# M2354 register map
File version: 1.0
Registers are 32-bit, read-write, reset 0x0 unless marked. A register's access mark holds for its fields unless they carry their own. Offsets are from the block's base; [hi:lo] are bit positions; {n}, {i} and the like mark numbered series; 'fields as' and 'values as' point back to an identical list.

## TAMPER — Tamper Register Map
Base 0x400BD000
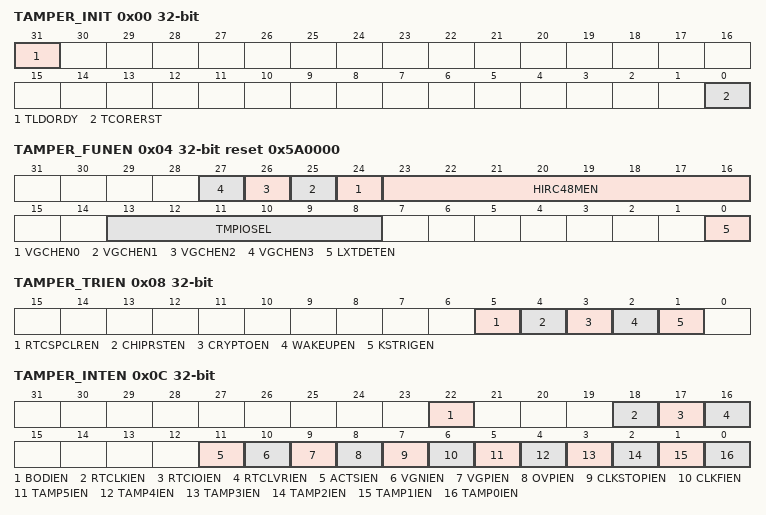
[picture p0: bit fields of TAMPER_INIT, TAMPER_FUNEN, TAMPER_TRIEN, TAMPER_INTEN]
0x00 TAMPER_INIT — Tamper Function Initiation Register
  [31] TLDORDY ro — Voltage Regulator Power Ready (Read Only)
    0=The power status of voltage regulator is not ready; 1=The power status of voltage regulator is ready
  [0] TCORERST — Tamper Core Reset
    0=Write 0x5500; the Tamper core block reset will be released; 1=Write 0x55AA; the Tamper core block will be reset
0x04 TAMPER_FUNEN reset 0x5A0000 — Tamper Block Function Enable Register
  [n+24] VGCHEN{n} (n=0..3) — Voltage Glitch Channel {n} Enable Bit. Note: To avoid the voltage glitch when the voltage channel is enabled, it is better to detect the voltage glitch about 150us after the channel is enabled.
    0=Voltage glitch channel {n} Disabled; 1=Voltage glitch channel {n} Enabled
  [23:16] HIRC48MEN — HIRC48M Enable Bit. The HIRC48M is disabled when these bits equal 0x5A, otherwise it will be enabled with any other values.
  [13:8] TMPIOSEL — Tamper I/O Detection Selection Bit
    0=Write 0x90/0xA0/0xB0/0xC0/0xD0/0xE0 for tamper I/O 0~5; the I/O tamper function is detected through RTC block; 1=Write 0x94/0xA4/0xB4/0xC4/0xD4/0xE4 for tamper I/O 0~5; the I/O tamper function is detected through Tamper block
  [0] LXTDETEN — LXT Clock Detection Enable Bit
    0=Write 0x40; the LXT clock detection Disabled; 1=Write 0x44; the LXT clock detection Enabled
0x08 TAMPER_TRIEN — Tamper Trigger Enable Register
  [5] RTCSPCLREN — RTC Spare Register Clear Enable Bit
    0=Tamper event trigger RTC spare register reset Disabled; 1=Tamper event trigger RTC spare register reset Enabled
  [4] CHIPRSTEN — Chip Reset Enable Bit
    0=Tamper event trigger chip reset Disabled; 1=Tamper event trigger chip reset Enabled
  [3] CRYPTOEN — Crypto Enable Bit
    0=Tamper event clear Crypto Disabled; 1=Tamper event clear Crypto Enabled
  [2] WAKEUPEN — Wakeup Enable Bit
    0=Tamper wakeup event Disabled; 1=Tamper wakeup event Enabled
  [1] KSTRIGEN — Key Store Trigger Enable Bit
    0=Tamper event is detected and to trigger Key Store Disabled; 1=Tamper event is detected and to trigger Key Store Enabled
0x0C TAMPER_INTEN — Tamper Event Interrupt Enable Register
  [22] BODIEN — BOD Event Interrupt Enable Bit
    0=Brown-out event interrupt Disabled; 1=Brown-out event interrupt Enabled
  [18] RTCLKIEN — RTC Clock Monitor Detection Event Interrupt Enable Bit
    0=RTC clock monitor event interrupt Disabled; 1=RTC clock monitor event interrupt Enabled
  [17] RTCIOIEN — RTC Tamper I/O Event Interrupt Enable Bit
    0=RTC tamper I/O detection event interrupt Disabled; 1=RTC tamper I/O detection event interrupt Enabled
  [16] RTCLVRIEN — RTC Low Voltage Detection Event Interrupt Enable Bit
    0=VBAT low voltage detection event interrupt Disabled; 1=VBAT low voltage detection event interrupt Enabled
  [11] ACTSIEN — Active Shield Event Interrupt Enable Bit
    0=Active shield event interrupt Disabled; 1=Active shield event interrupt Enabled
  [10] VGNIEN — Voltage Glitch Negative Detection Event Interrupt Enable Bit
    0=LDO_CAP negative glitch event interrupt Disabled; 1=LDO_CAP negative glitch event interrupt Enabled
  [9] VGPIEN — Voltage Glitch Positive Detection Event Interrupt Enable Bit
    0=LDO_CAP positive glitch event interrupt Disabled; 1=LDO_CAP positive glitch event interrupt Enabled
  [8] OVPIEN — VDD Over Voltage Protect Detection Interrupt Enable Bit. Note: The function enable of the over voltage detection is defined in system manager.
    0=Detect VDD over voltage protect detection interrupt Disabled; 1=Detect VDD over voltage protect detection interrupt Enabled
  [7] CLKSTOPIEN — LXT Clock Frequency Monitor Stop Event Interrupt Enable Bit
    0=LXT frequency stop event interrupt Disabled; 1=LXT frequency stop event interrupt Enabled
  [6] CLKFIEN — LXT Clock Frequency Monitor Fail Event Interrupt Enable Bit
    0=LXT frequency fail event interrupt Disabled; 1=LXT frequency fail event interrupt Enabled
  [5] TAMP5IEN — Tamper 5 or Pair 2 Event Interrupt Enable Bit
    0=Tamper 5 or Pair 2 event interrupt Disabled; 1=Tamper 5 or Pair 2 event interrupt Enabled
  [4] TAMP4IEN — Tamper 4 Event Interrupt Enable Bit
    0=Tamper 4 event interrupt Disabled; 1=Tamper 4 event interrupt Enabled
  [3] TAMP3IEN — Tamper 3 or Pair 1 Event Interrupt Enable Bit
    0=Tamper 3 or Pair 1 event interrupt Disabled; 1=Tamper 3 or Pair 1 event interrupt Enabled
  [2] TAMP2IEN — Tamper 2 Event Interrupt Enable Bit
    0=Tamper 2 event interrupt Disabled; 1=Tamper 2 event interrupt Enabled
  [1] TAMP1IEN — Tamper 1 or Pair 0 Event Interrupt Enable Bit
    0=Tamper 1 or Pair 0 event interrupt Disabled; 1=Tamper 1 or Pair 0 event interrupt Enabled
  [0] TAMP0IEN — Tamper 0 Event Interrupt Enable Bit
    0=Tamper 0 event interrupt Disabled; 1=Tamper 0 event interrupt Enabled
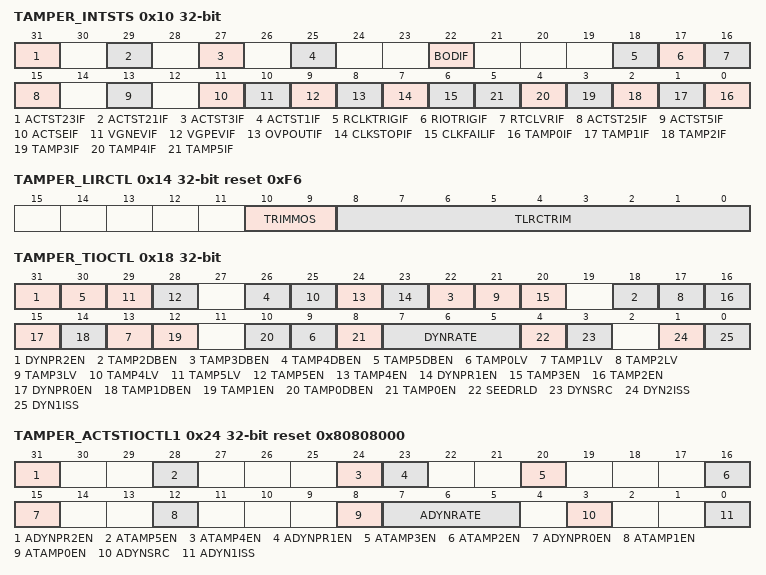
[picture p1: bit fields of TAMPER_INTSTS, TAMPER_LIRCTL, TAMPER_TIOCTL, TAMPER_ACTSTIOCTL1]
0x10 TAMPER_INTSTS — Tamper Interrupt Status Register
  [31] ACTST23IF — 2th Active Shield Tamper 3 Event Interrupt Flag. Note: Write 1 to clear this bit.
    0=No Active shield Tamper 3 event interrupt flag is generated; 1=2th Active shield Tamper 3 event interrupt flag is generated
  [29] ACTST21IF — 2th Active Shield Tamper 1 Event Interrupt Flag. Note: Write 1 to clear this bit.
    0=No Active shield Tamper 1 event interrupt flag is generated; 1=2th Active shield Tamper 1 event interrupt flag is generated
  [27] ACTST3IF — Active Shield Tamper 3 Event Interrupt Flag. Note: Write 1 to clear this bit.
    0=No Active shield Tamper 3 event interrupt flag is generated; 1=Active shield Tamper 3 event interrupt flag is generated
  [25] ACTST1IF — Active Shield Tamper 1 Event Interrupt Flag. Note: Write 1 to clear this bit.
    0=No Active shield Tamper 1 event interrupt flag is generated; 1=Active shield Tamper 1 event interrupt flag is generated
  [22] BODIF — BOD Event Interrupt Flag. Note: It is used to detect the LDO_CAP. Write 1 to clear this bit.
    0=Brown-out event interrupt flag is no detected; 1=Brown-out interrupt flag is detected
  [18] RCLKTRIGIF — RTC Clock Monitor Detection Event Interrupt Flag
    0=There is no RTC clock monitor detection event interrupt flag; 1=There is RTC clock monitor detection event interrupt flag
  [17] RIOTRIGIF — RTC Tamper I/O Event Interrupt Flag
    0=There is no RTC tamper I/O detection event interrupt flag; 1=There is RTC tamper I/O detection event interrupt flag
  [16] RTCLVRIF — RTC Low Voltage Detection Event Interrupt Flag
    0=VBAT low voltage detection event interrupt flag is not detected; 1=VBAT low voltage detection event interrupt flag is detected
  [15] ACTST25IF — Active Shield Tamper 5 Event Interrupt Flag. Note: Write 1 to clear this bit.
    0=No Active shield Tamper 5 event interrupt flag is generated; 1=2th Active shield Tamper 5 event interrupt flag is generated
  [13] ACTST5IF — Active Shield Tamper 5 Event Interrupt Flag. Note: Write 1 to clear this bit.
    0=No Active shield Tamper 5 event interrupt flag is generated; 1=Active shield Tamper 5 event interrupt flag is generated
  [11] ACTSEIF — Active Shield Event Detection Interrupt Flag. Note: Write 1 to clear this bit after all of ACTSTxIF bits have been cleaned.
    0=Active shield event interrupt flag is not detected; 1=Active shield event interrupt flag is detected including the voltage of voltage regulator and GND attack
  [10] VGNEVIF — Voltage Glitch Negative Detection Interrupt Flag. Note: It can be written 1 to clear only (No clear by TCORERST)
    0=LDO_CAP negative glitch is not detected; 1=LDO_CAP negative glitch is detected
  [9] VGPEVIF — Voltage Glitch Positive Detection Interrupt Flag. Note: It can be written 1 to clear only (No clear by TCORERST)
    0=LDO_CAP positive glitch is not detected; 1=LDO_CAP positive glitch is detected
  [8] OVPOUTIF — VDD Over Voltage Event Interrupt Flag. Note: Write 1 to clear this bit.
    0=VDD no over voltage is detected; 1=VDD over voltage is detected
  [7] CLKSTOPIF — LXT Clock Frequency Monitor Stop Event Interrupt Flag. Note 1: Write 1 to clear this bit to 0. Note 2: LXT detector will be automatically disabled when Fail/Stop flag rises, and resumes after Fail/Stop flag is cleared.
    0=LXT frequency is normal; 1=LXT frequency is almost stopped
  [6] CLKFAILIF — LXT Clock Frequency Monitor Fail Event Interrupt Flag. Note 1: Write 1 to clear this bit to 0. Note 2: LXT detector will be automatically disabled when Fail/Stop flag rises, and resumes after Fail/Stop flag is cleared.
    0=LXT frequency is normal; 1=LXT frequency is abnormal
  [n] TAMP{n}IF (n=0..5) — Tamper {n} Event Interrupt Flag. Note: Write 1 to clear this bit.
    0=No Tamper {n} event interrupt flag is generated; 1=Tamper {n} event interrupt flag is generated
0x14 TAMPER_LIRCTL reset 0xF6 — Tamper LIRC Control Register
  [10:9] TRIMMOS — Tamper TLIRC32K Trim MOS Value. TLIRC32K trim MOS value setting
  [8:0] TLRCTRIM — Tamper TLIRC32K Trim Value. TLIRC32K trim value setting
0x18 TAMPER_TIOCTL — Tamper I/O Function Control Register
  [31] DYNPR2EN — Dynamic Pair 2 Enable Bit
    0=Static detect; 1=Dynamic detect
  [4n+10] TAMP{n}DBEN (n=2..5) — Tamper {n} De-bounce Enable Bit
    0=Tamper {n} de-bounce Disabled; 1=Tamper {n} de-bounce Enabled. Tamper detection pin will sync 1 RTC clock
  [4n+9] TAMP{n}LV (n=0..5) — Tamper {n} Level. This bit depends on level attribute of tamper pin for static tamper detection.
    0=Detect voltage level is low; 1=Detect voltage level is high
  [28] TAMP5EN — Tamper 5 Detect Enable Bit. Note: The reference is RTC-clock. Tamper detector needs sync 2 ~ 3 RTC-clock.
    0=Tamper 5 detect Disabled; 1=Tamper 5 detect Enabled
  [24] TAMP4EN — Tamper4 Detect Enable Bit. Note: The reference is RTC-clock. Tamper detector needs sync 2 ~ 3 RTC-clock.
    0=Tamper 4 detect Disabled; 1=Tamper 4 detect Enabled
  [23] DYNPR1EN — Dynamic Pair 1 Enable Bit
    0=Static detect; 1=Dynamic detect
  [20] TAMP3EN — Tamper 3 Detect Enable Bit. Note: The reference is RTC-clock. Tamper detector needs sync 2 ~ 3 RTC-clock.
    0=Tamper 3 detect Disabled; 1=Tamper 3 detect Enabled
  [16] TAMP2EN — Tamper 2 Detect Enable Bit. Note: The reference is RTC-clock. Tamper detector need sync 2 ~ 3 RTC-clock.
    0=Tamper 2 detect Disabled; 1=Tamper 2 detect Enabled
  [15] DYNPR0EN — Dynamic Pair 0 Enable Bit
    0=Static detect; 1=Dynamic detect
  [14] TAMP1DBEN — Tamper 1 De-bounce Enable Bit
    0=Tamper 1 de-bounce Disabled; 1=Tamper 1 de-bounce Enabled, tamper detection pin will sync 1 RTC clock
  [12] TAMP1EN — Tamper 1 Detect Enable Bit. Note: The reference is RTC-clock. Tamper detector needs sync 2 ~ 3 RTC-clock.
    0=Tamper 1 detect Disabled; 1=Tamper 1 detect Enabled
  [10] TAMP0DBEN — Tamper 0 De-bounce Enable Bit
    0=Tamper 0 de-bounce Disabled; 1=Tamper 0 de-bounce Enabled. Tamper detection pin will sync 1 RTC clock
  [8] TAMP0EN — Tamper0 Detect Enable Bit. Note: The reference is RTC-clock. Tamper detector needs sync 2 ~ 3 RTC-clock.
    0=Tamper 0 detect Disabled; 1=Tamper 0 detect Enabled
  [7:5] DYNRATE — Dynamic Change Rate. This item is choice the dynamic tamper output change rate. Note: After revising this field, setting SEEDRLD (TAMPER_TIOCTL[4]) can reload change rate immediately.
    {v}={v+26} * RTC_CLK (v=0..3); {v}={v+206} * RTC_CLK (v=4..7)
  [4] SEEDRLD — Reload New Seed for PRNG Engine. Setting this bit, the tamper configuration will be reloaded. Note 1: Before this bit is set, the tamper configuration should be set to complete and this bit will be auto clear to 0 after reload new seed completed. Note 2: The reference is RTC-clock. Tamper detector needs sync 2 ~ 3 RTC-clock.
    0=Generating key based on the current seed; 1=Reload new seed
  [3] DYNSRC — Dynamic Reference Pattern. This field determines the new reference pattern when current pattern run out in dynamic pair mode. Note: After this bit is modified, the SEEDRLD (TAMPER_TIOCTL[4]) should be set.
    0=The new reference pattern is generated by random number generator when the reference pattern run out; 1=The new reference pattern is repeated from SEED (TAMPER_SEED[31:0]) when the reference pattern run out
  [1] DYN2ISS — Dynamic Pair 2 Input Source Select. This bit determines Tamper 5 input is from Tamper 4 or Tamper 0 in dynamic mode. Note: This bit has effect only when DYNPR2EN (TAMPER_TIOCTL[31]) and DYNPR0EN (TAMPER_TIOCTL[15]) are set.
    0=Tamper input is from Tamper 4; 1=Tamper input is from Tamper 0
  [0] DYN1ISS — Dynamic Pair 1 Input Source Select. This bit determines Tamper 3 input is from Tamper 2 or Tamper 0 in dynamic mode. Note: This bit is effective only when DYNPR1EN (TAMPER_TIOCTL[23]) and DYNPR0EN (TAMPER_TIOCTL[15]) are set.
    0=Tamper input is from Tamper 2; 1=Tamper input is from Tamper 0
0x1C TAMPER_SEED — Tamper Seed Value Control Register
  [31:0] SEED — Seed value.
0x20 TAMPER_SEED2 — Tamper 2nd Seed Value Control Register
  [31:0] SEED2 — Seed value. These seed value are used for 2nd active shield I/O.
0x24 TAMPER_ACTSTIOCTL1 reset 0x80808000 — Tamper Active Shield Tamper I/O Function Control Register 1
  [31] ADYNPR2EN — Active Shied Dynamic Pair 2 Enable Bit
    0=Static detect (Not supported); 1=Dynamic detect
  [28] ATAMP5EN — Active Tamper 5 Detect Enable Bit. Note: The reference is TLIRC 32K-clock. Tamper detector need sync 2 ~ 3 TLIRC 32K-clock.
    0=Tamper 5 detect Disabled; 1=Tamper 5 detect Enabled
  [24] ATAMP4EN — Active Tamper4 Detect Enable Bit. Note: The reference is TLIRC 32K-clock. Tamper detector need sync 2 ~ 3 TLIRC 32K-clock.
    0=Tamper 4 detect Disabled; 1=Tamper 4 detect Enabled
  [23] ADYNPR1EN — Active Shied Dynamic Pair 1 Enable Bit
    0=Static detect (Not supported); 1=Dynamic detect
  [20] ATAMP3EN — Active Shied Tamper 3 Detect Enable Bit. Note: The reference is TLIRC 32K-clock. Tamper detector needs sync 2 ~ 3 TLIRC 32K-clock.
    0=Tamper 3 detect Disabled; 1=Tamper 3 detect Enabled
  [16] ATAMP2EN — Active Shied Tamper 2 Detect Enable Bit. Note: The reference is TLIRC 32K-clock. Tamper detector needs sync 2 ~ 3 TLIRC 32K-clock.
    0=Tamper 2 detect Disabled; 1=Tamper 2 detect Enabled
  [15] ADYNPR0EN — Active Shied Dynamic Pair 0 Enable Bit
    0=Static detect (Not supported); 1=Dynamic detect
  [12] ATAMP1EN — Active Shied Tamper 1 Detect Enable Bit. Note: The reference is TLIRC 32K-clock. Tamper detector needs sync 2 ~ 3 TLIRC 32K-clock.
    0=Tamper 1 detect Disabled; 1=Tamper 1 detect Enabled
  [8] ATAMP0EN — Active Shied Tamper0 Detect Enable Bit. Note: The reference is TLIRC 32K-clock. Tamper detector need sync 2 ~ 3 TLIRC 32K-clock.
    0=Tamper 0 detect Disabled; 1=Tamper 0 detect Enabled
  [7:5] ADYNRATE — Active Shied Dynamic Change Rate. Use the bits to choose the dynamic tamper output change rate. Note: After this field is modified, setting SEEDRLD (TAMPER_TIOCTL[4]) can reload the change rate immediately.
    {v}={v+210} * TLIRC32K (v=0..7)
  [3] ADYNSRC — Active Shied Dynamic Reference Pattern. This field determines the new reference pattern when current pattern run out in dynamic pair mode. Note: After this bit is modified, the SEEDRLD (TAMPER_TIOCTL[4]) should be set.
    values as TAMPER_TIOCTL.DYNSRC
  [0] ADYN1ISS — Active Shied Dynamic Pair 1 Input Source Select. This bit determines Tamper 3 input is from Tamper 2 or Tamper 0 in dynamic mode. Note: This bit is effective only when ADYNPR1EN (TAMPER_ACTSTIOCTL1[23]) and ADYNPR0EN (TAMPER_ACTSTIOCTL1[15]) are set.
    values as TAMPER_TIOCTL.DYN1ISS
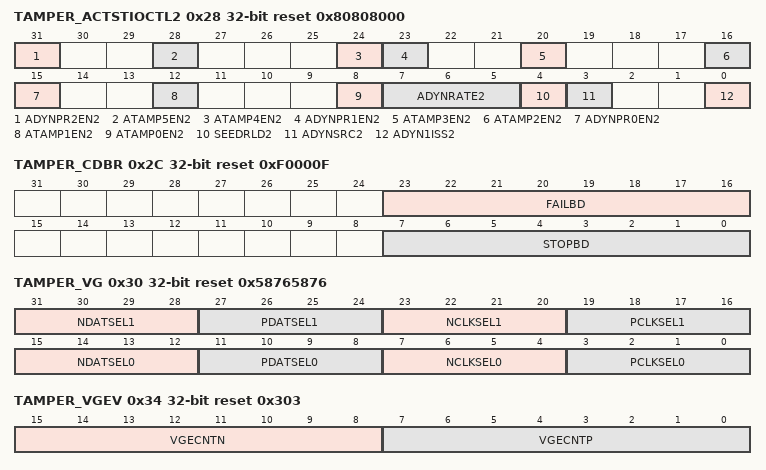
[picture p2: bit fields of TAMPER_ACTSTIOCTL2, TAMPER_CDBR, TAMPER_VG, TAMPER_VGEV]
0x28 TAMPER_ACTSTIOCTL2 reset 0x80808000 — Tamper Active Shield Tamper I/O Function Control Register 2
  [31] ADYNPR2EN2 — Active Shied Dynamic Pair 2 Enable Bit 2
    0=Static detect (Not supported); 1=Dynamic detect
  [28] ATAMP5EN2 — Active Tamper 5 Detect Enable Bit 2. Note: The reference is TLIRC 32K-clock. Tamper detector need sync 2 ~ 3 TLIRC 32K-clock.
    0=Tamper 5 detect Disabled; 1=Tamper 5 detect Enabled
  [24] ATAMP4EN2 — Active Shied Tamper4 Detect Enable Bit 2. Note: The reference is TLIRC 32K-clock. Tamper detector need sync 2 ~ 3 TLIRC 32K-clock.
    0=Tamper 4 detect Disabled; 1=Tamper 4 detect Enabled
  [23] ADYNPR1EN2 — Active Shied Dynamic Pair 1 Enable Bit 2
    0=Static detect (Not supported); 1=Dynamic detect
  [20] ATAMP3EN2 — Active Shied Tamper 3 Detect Enable Bit 2. Note: The reference is TLIRC 32K-clock. Tamper detector needs sync 2 ~ 3 TLIRC 32K-clock.
    0=Tamper 3 detect Disabled; 1=Tamper 3 detect Enabled
  [16] ATAMP2EN2 — Active Shied Tamper 2 Detect Enable Bit 2. Note: The reference is TLIRC 32K-clock. Tamper detector needs sync 2 ~ 3 TLIRC 32K-clock.
    0=Tamper 2 detect Disabled; 1=Tamper 2 detect Enabled
  [15] ADYNPR0EN2 — Active Shied Dynamic Pair 0 Enable Bit 2
    0=Static detect (Not supported); 1=Dynamic detect
  [12] ATAMP1EN2 — Active Shied Tamper 1 Detect Enable Bit 2. Note: The reference is TLIRC 32K-clock. Tamper detector needs sync 2 ~ 3 TLIRC 32K-clock.
    0=Tamper 1 detect Disabled; 1=Tamper 1 detect Enabled
  [8] ATAMP0EN2 — Active Shied Tamper0 Detect Enable Bit 2. Note: The reference is TLIRC 32K-clock. Tamper detector needs sync 2 ~ 3 TLIRC 32K-clock.
    0=Tamper 0 detect Disabled; 1=Tamper 0 detect Enabled
  [7:5] ADYNRATE2 — Active Shied Dynamic Change Rate 2. Use the bits to choose the dynamic tamper output change rate. Note: After this field is modified, setting SEEDRLD2 (TAMPER_ACTSTIOCTL2[4]) can reload change rate immediately.
    {v}={v+210} * TLIRC32K (v=0..7)
  [4] SEEDRLD2 — Reload New Seed for PRNG Engine 2. Setting this bit, the tamper configuration will be reloaded. Note 1: Before this bit is set, the tamper configuration should be set to complete and this bit will be auto clear to 0 after reload new seed completed. Note 2: The reference is TLIRC 32K-clock. Tamper detector needs sync 2 ~ 3 TLIRC 32K-clock.
    values as TAMPER_TIOCTL.SEEDRLD
  [3] ADYNSRC2 — Active Shied Dynamic Reference Pattern 2. This field determines the new reference pattern when current pattern run out in dynamic pair mode. Note: After this bit is modified, the SEEDRLD2 (TAMPER_ACTSTIOCTL2[4]) should be set.
    0=The new reference pattern is generated by random number generator when the reference pattern run out; 1=The new reference pattern is repeated from SEED2 (TAMPER_SEED2[31:0]) when the reference pattern run out
  [0] ADYN1ISS2 — Active Shied Dynamic Pair 1 Input Source Select 2. This bit determines if Tamper 3 input is from Tamper 2 or Tamper 0 in dynamic mode. Note: This bit is effective only when ADYNPR1EN2 (TAMPER_ACTSTIOCTL2[23]) and ADYNPR0EN2 (TAMPER_ACTSTIOCTL2[15]) are set.
    values as TAMPER_TIOCTL.DYN1ISS
0x2C TAMPER_CDBR reset 0xF0000F — Tamper Clock Frequency Detector Boundary Register
  [23:16] FAILBD — LXT Clock Frequency Detector Fail Boundary. The bits define the fail value of frequency monitor window. When LXT frequency monitor counter lower than Clock Frequency Detector Fail Boundary, the LXT frequency detect fail interrupt flag will set to 1. Note: The boundary is defined as the minimum value of LXT among 256 Tamper clock time.
  [7:0] STOPBD — LXT Clock Frequency Detector Stop Boundary. The bits define the stop value of frequency monitor window. When LXT frequency monitor counter lower than Clock Frequency Detector Stop Boundary, the LXT frequency detect stop interrupt flag will set to 1. Note: The boundary is defined as the maximum value of LXT among 256 Tamper clock time.
0x30 TAMPER_VG reset 0x58765876 — Tamper Voltage Glitch Control Register
  [31:28] NDATSEL1 — PL1 Negative Data Trim Range. The setting value of the negative data tolerance. One step is about 2.5% tolerance. The maximum tolerance is 20%.
  [27:24] PDATSEL1 — PL1 Positive Data Trim Range. The setting value of the positive data tolerance. One step is about 2.5% tolerance. The maximum tolerance is 20%.
  [23:20] NCLKSEL1 — PL1 Negative Clock Trim Range. The setting value of the negative clock tolerance. One step is about 2.5% tolerance. The maximum tolerance is 20%.
  [19:16] PCLKSEL1 — PL1 Positive Clock Trim Range. The setting value of the positive clock tolerance. One step is about 2.5% tolerance. The maximum tolerance is 20%. Note: PL1 means the power level is 1.2V
  [15:12] NDATSEL0 — PL0 Negative Data Trim Range. The setting value of the negative data tolerance. One step is about 2.5% tolerance. The maximum tolerance is 20%.
  [11:8] PDATSEL0 — PL0 Positive Data Trim Range. The setting value of the positive data tolerance. One step is about 2.5% tolerance. The maximum tolerance is 20%.
  [7:4] NCLKSEL0 — PL0 Negative Clock Trim Range. The setting value of the negative clock tolerance. One step is about 2.5% tolerance. The maximum tolerance is 20%.
  [3:0] PCLKSEL0 — PL0 Positive Clock Trim Range. The setting value of the positive clock tolerance. One step is about 2.5% tolerance. The maximum tolerance is 20%. Note: PL0 means the power level is 1.26V. The power level is controlled in system manager
0x34 TAMPER_VGEV reset 0x303 — Tamper Voltage Glitch Event Tolerance Control Register
  [15:8] VGECNTN — Negative Voltage Glitch Error Tolerance. The value indicates the tolerance count for negative voltage glitch event.
  [7:0] VGECNTP — Positive Voltage Glitch Error Tolerance. The value indicates the tolerance count for positive voltage glitch event.
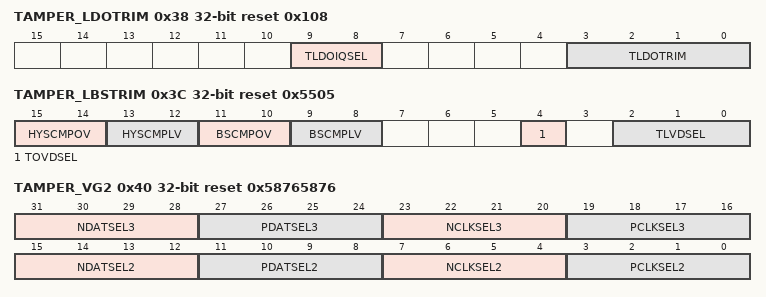
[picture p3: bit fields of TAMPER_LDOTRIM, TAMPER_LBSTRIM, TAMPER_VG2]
0x38 TAMPER_LDOTRIM reset 0x108 — Tamper LDO Trim Value Control Register
  [9:8] TLDOIQSEL — Voltage Regulator Qu Current Selection. Indicates the Qu current selection of voltage regulator.
  [3:0] TLDOTRIM — Voltage Regulator Output Voltage Trim. The value indicates the trim value of the voltage regulator output voltage.
0x3C TAMPER_LBSTRIM reset 0x5505 — Tamper LDO BIAS Trim Value Control Register
  [15:14] HYSCMPOV — Over-shoot Detect Comparator Hysteresis Trim Bits. The value indicates the trim value of the over-shoot detection comparator of hysteresis trim level
  [13:12] HYSCMPLV — Under-shoot Detect Comparator Hysteresis Trim Bits. The value indicates the trim value of the under-shoot detection comparator of hysteresis trim level
  [11:10] BSCMPOV — Over-shoot Detect Comparator Current Trim Bits. The value indicates the trim value of the over-shoot detection comparator current trim level
  [9:8] BSCMPLV — Under-shoot Detect Comparator Current Trim Bits. The value indicates the trim value of the under-shoot detection comparator current trim level
  [4] TOVDSEL — Over-shoot Detect Level Trim Bits. The value indicates the trim value of the over-shoot detection level
  [2:0] TLVDSEL — Under-shoot Detect Level Trim Bits. The value indicates the trim value of the under-shoot detection level
0x40 TAMPER_VG2 reset 0x58765876 — Tamper Voltage Glitch Control Register 2
  [31:28] NDATSEL3 — PL3 Negative Data Trim Range. The setting value of the negative data tolerance. One step is about 2.5% tolerance. The maximum tolerance is 20%.
  [27:24] PDATSEL3 — PL3 Positive Data Trim Range. The setting value of the positive data tolerance. One step is about 2.5% tolerance. The maximum tolerance is 20%.
  [23:20] NCLKSEL3 — PL3 Negative Clock Trim Range. The setting value of the negative clock tolerance. One step is about 2.5% tolerance. The maximum tolerance is 20%.
  [19:16] PCLKSEL3 — PL3 Positive Clock Trim Range. The setting value of the positive clock tolerance. One step is about 2.5% tolerance. The maximum tolerance is 20%. Note: PL3 means the power level is 0.9V
  [15:12] NDATSEL2 — PL2 Negative Data Trim Range. The setting value of the negative data tolerance. One step is about 2.5% tolerance. The maximum tolerance is 20%.
  [11:8] PDATSEL2 — PL2 Positive Data Trim Range. The setting value of the positive data tolerance. One step is about 2.5% tolerance. The maximum tolerance is 20%.
  [7:4] NCLKSEL2 — PL2 Negative Clock Trim Range. The setting value of the negative clock tolerance. One step is about 2.5% tolerance. The maximum tolerance is 20%.
  [3:0] PCLKSEL2 — PL2 Positive Clock Trim Range. The setting value of the positive clock tolerance. One step is about 2.5% tolerance. The maximum tolerance is 20%. Note: PL2 means the power level is 1.1V. The power level is controlled in system manager.
